AUTOSAR XML (schema 4-0-3)
package /ComponentTypes
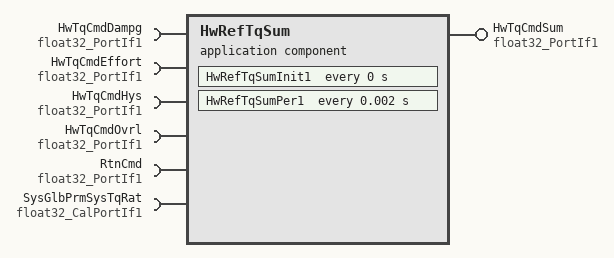
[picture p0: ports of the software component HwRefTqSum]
  application sw component type HwRefTqSum
    provide port HwTqCmdSum: nonqueued-sender-com-spec{data-element=Val, init-value=0}, provided-interface=float32_PortIf1
    6 x require port:
      HwTqCmdDampg: nonqueued-receiver-com-spec{data-element=Val, filter=data-filter-type=ALWAYS, init-value=0}, required-interface=float32_PortIf1
      HwTqCmdEffort: nonqueued-receiver-com-spec{data-element=Val, filter=data-filter-type=ALWAYS, init-value=0}, required-interface=float32_PortIf1
      HwTqCmdHys: nonqueued-receiver-com-spec{data-element=Val, filter=data-filter-type=ALWAYS, init-value=0}, required-interface=float32_PortIf1
      HwTqCmdOvrl: nonqueued-receiver-com-spec{data-element=Val, filter=data-filter-type=ALWAYS, init-value=0}, required-interface=float32_PortIf1
      RtnCmd: nonqueued-receiver-com-spec{data-element=Val, filter=data-filter-type=ALWAYS, init-value=0}, required-interface=float32_PortIf1
      SysGlbPrmSysTqRat: parameter-require-com-spec{init-value=20, parameter=Val}, required-interface=float32_CalPortIf1
    behavior HwRefTqSum_InternalBehavior
      timing event HwRefTqSum_InitEvent: start-on-event=HwRefTqSumInit1, period=0
      timing event TMT_HwRefTqSumPer1: start-on-event=HwRefTqSumPer1, period=0.002
      runnable HwRefTqSumInit1
      runnable HwRefTqSumPer1: minimum-start-interval=0.002
        data-receive-point-by-arguments:
          5 x access:
            REC_HwTqCmdDampg_Val: accessed-variable=HwTqCmdDampg.Val
            REC_HwTqCmdEffort_Val: accessed-variable=HwTqCmdEffort.Val
            REC_HwTqCmdHys_Val: accessed-variable=HwTqCmdHys.Val
            REC_HwTqCmdOvrl_Val: accessed-variable=HwTqCmdOvrl.Val
            REC_RtnCmd_Val: accessed-variable=RtnCmd.Val
        data-send-points:
          access SEND_HwTqCmdSum_Val: accessed-variable=HwTqCmdSum.Val
  swc implementation HwRefTqSum_Implementation: behavior=HwRefTqSum_InternalBehavior
    code-descriptors:
      code Default: artifact-descriptors=autosar-engineering-object={short-label=Default, category=SWSRC}
